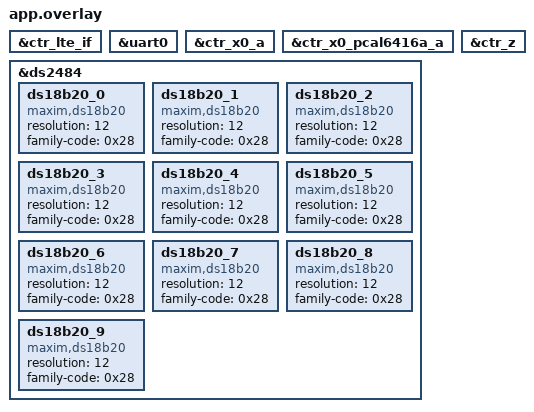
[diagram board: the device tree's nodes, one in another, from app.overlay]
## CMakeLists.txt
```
#
# Copyright (c) 2024 HARDWARIO a.s.
#
#  SPDX-License-Identifier: LicenseRef-HARDWARIO-5-Clause
#

cmake_minimum_required(VERSION 3.20.0)

set(ENV{FW_BUNDLE} "com.hardwario.chester.input")
set(ENV{FW_VERSION} "v1.0.0")
set(ENV{FW_NAME} "CHESTER Input")

find_package(Zephyr REQUIRED HINTS $ENV{ZEPHYR_BASE})

project(chester-input)

target_sources(app PRIVATE src/app_sensor.c)
target_sources(app PRIVATE src/main.c)
target_sources(app PRIVATE src/app_shell.c)
target_sources(app PRIVATE src/app_init.c)
target_sources(app PRIVATE src/app_data.c)
target_sources(app PRIVATE src/app_power.c)
target_sources(app PRIVATE src/app_send.c)
target_sources(app PRIVATE src/app_config.c)
target_sources(app PRIVATE src/app_work.c)
target_sources(app PRIVATE src/app_handler.c)
target_sources(app PRIVATE src/app_backup.c)
target_sources(app PRIVATE src/app_cbor.c)
```

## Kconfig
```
#
# Copyright (c) 2024 HARDWARIO a.s.
#
# SPDX-License-Identifier: LicenseRef-HARDWARIO-5-Clause
#

menu "Application"

# CHESTER INPUT Project | INPUT Variant 

# LTE 
config SHIELD_CTR_LTE
	bool "Enable SHIELD_CTR_LTE"
	default y 

config CTR_LTE
	default y
# X0_A 
config SHIELD_CTR_X0_A
	bool "Enable SHIELD_CTR_X0_A"
	default y 

config CTR_X0
	default y
# Z 
config SHIELD_CTR_Z
	bool "Enable SHIELD_CTR_Z"
	default y 

config CTR_Z
	default y

config I2C
	default y
# DS18B20 
config SHIELD_CTR_DS18B20
	bool "Enable SHIELD_CTR_DS18B20"
	default y 

config CTR_DS18B20
	default y

endmenu

menu "Zephyr Kernel"
source "Kconfig.zephyr"
endmenu
```

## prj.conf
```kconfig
#
# Copyright (c) 2024 HARDWARIO a.s.
#
#  SPDX-License-Identifier: LicenseRef-HARDWARIO-5-Clause
#

# Configurations
CONFIG_ADC_SHELL=y
CONFIG_CTR_ACCEL=y
CONFIG_CTR_ADC=y
CONFIG_CTR_BATT=y
CONFIG_CTR_BUTTON=y
CONFIG_CTR_BLE=y
CONFIG_CTR_BUF=y
CONFIG_CTR_DEFAULTS=y
CONFIG_CTR_EDGE=y
CONFIG_CTR_INFO=y
CONFIG_CTR_LED=y
CONFIG_CTR_LOG=y
CONFIG_CTR_LTE_CLKSYNC=y
CONFIG_CTR_RTC=y
CONFIG_CTR_THERM=y
CONFIG_CTR_WDOG=y
CONFIG_ENTROPY_GENERATOR=y
CONFIG_TINYCRYPT=y
CONFIG_TINYCRYPT_SHA256=y
CONFIG_ZCBOR=y
CONFIG_ZCBOR_STOP_ON_ERROR=y

# Extra configurations
CONFIG_ADC_TLA2021_INIT_PRIORITY=60
CONFIG_ADC_SHELL=n

# USER CODE BEGIN Config 
# USER CODE END Config
```

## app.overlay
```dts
/*
 * Copyright (c) 2024 HARDWARIO a.s.
 *
 * SPDX-License-Identifier: LicenseRef-HARDWARIO-5-Clause
 */

/* CHESTER INPUT Project | INPUT Variant */

/* LTE  */
&ctr_lte_if {
	status = "okay";
};

&uart0 {
	status = "okay";
};
/* X0_A  */
&ctr_x0_a {
	status = "okay";
};

&ctr_x0_pcal6416a_a {
	status = "okay";
};
/* Z  */
&ctr_z {
	status = "okay";
};
/* DS18B20  */
&ds2484 {
	ds18b20_0: ds18b20_0 {
		compatible = "maxim,ds18b20";
		resolution = <12>;
		family-code = <0x28>;
	};

	ds18b20_1: ds18b20_1 {
		compatible = "maxim,ds18b20";
		resolution = <12>;
		family-code = <0x28>;
	};

	ds18b20_2: ds18b20_2 {
		compatible = "maxim,ds18b20";
		resolution = <12>;
		family-code = <0x28>;
	};

	ds18b20_3: ds18b20_3 {
		compatible = "maxim,ds18b20";
		resolution = <12>;
		family-code = <0x28>;
	};

	ds18b20_4: ds18b20_4 {
		compatible = "maxim,ds18b20";
		resolution = <12>;
		family-code = <0x28>;
	};

	ds18b20_5: ds18b20_5 {
		compatible = "maxim,ds18b20";
		resolution = <12>;
		family-code = <0x28>;
	};

	ds18b20_6: ds18b20_6 {
		compatible = "maxim,ds18b20";
		resolution = <12>;
		family-code = <0x28>;
	};

	ds18b20_7: ds18b20_7 {
		compatible = "maxim,ds18b20";
		resolution = <12>;
		family-code = <0x28>;
	};

	ds18b20_8: ds18b20_8 {
		compatible = "maxim,ds18b20";
		resolution = <12>;
		family-code = <0x28>;
	};

	ds18b20_9: ds18b20_9 {
		compatible = "maxim,ds18b20";
		resolution = <12>;
		family-code = <0x28>;
	};
};
```

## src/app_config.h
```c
/*
 * Copyright (c) 2024 HARDWARIO a.s.
 *
 * SPDX-License-Identifier: LicenseRef-HARDWARIO-5-Clause
 */

#ifndef APP_CONFIG_H_
#define APP_CONFIG_H_

/* Zephyr includes */
#include <zephyr/shell/shell.h>

/* Standard includes */
#include <stdbool.h>
#include <stddef.h>

/* USER CODE BEGIN Includes */
/* USER CODE END Includes */

#ifdef __cplusplus
extern "C" {
#endif

enum app_config_input_type {
	APP_CONFIG_INPUT_TYPE_NPN = 0,
	APP_CONFIG_INPUT_TYPE_PNP = 1,
};

struct app_config {
	enum app_config_input_type trigger_input_type;
	enum app_config_input_type counter_input_type;
	int interval_report;
	int event_report_delay;
	int event_report_rate;
	bool backup_report_connected;
	bool backup_report_disconnected;
	int trigger_duration_active;
	int trigger_duration_inactive;
	int trigger_cooldown_time;
	bool trigger_report_active;
	bool trigger_report_inactive;
	int counter_interval_aggreg;
	int counter_duration_active;
	int counter_duration_inactive;
	int counter_cooldown_time;
	int analog_interval_sample;
	int analog_interval_aggreg;
	int hygro_interval_sample;
	int hygro_interval_aggreg;
	int w1_therm_interval_sample;
	int w1_therm_interval_aggreg;

	/* USER CODE BEGIN Struct Variables */
	/* USER CODE END Struct Variables */
};

extern struct app_config g_app_config;

/* USER CODE BEGIN Variables */
/* USER CODE END Variables */

int app_config_cmd_config_show(const struct shell *shell, size_t argc, char **argv);
int app_config_cmd_config_interval_report(const struct shell *shell, size_t argc, char **argv);
int app_config_cmd_config_event_report_delay(const struct shell *shell, size_t argc, char **argv);
int app_config_cmd_config_event_report_rate(const struct shell *shell, size_t argc, char **argv);
int app_config_cmd_config_backup_report_connected(const struct shell *shell, size_t argc, char **argv);
int app_config_cmd_config_backup_report_disconnected(const struct shell *shell, size_t argc, char **argv);
int app_config_cmd_config_trigger_duration_active(const struct shell *shell, size_t argc, char **argv);
int app_config_cmd_config_trigger_duration_inactive(const struct shell *shell, size_t argc, char **argv);
int app_config_cmd_config_trigger_cooldown_time(const struct shell *shell, size_t argc, char **argv);
int app_config_cmd_config_trigger_report_active(const struct shell *shell, size_t argc, char **argv);
int app_config_cmd_config_trigger_report_inactive(const struct shell *shell, size_t argc, char **argv);
int app_config_cmd_config_counter_interval_aggreg(const struct shell *shell, size_t argc, char **argv);
int app_config_cmd_config_counter_duration_active(const struct shell *shell, size_t argc, char **argv);
int app_config_cmd_config_counter_duration_inactive(const struct shell *shell, size_t argc, char **argv);
int app_config_cmd_config_counter_cooldown_time(const struct shell *shell, size_t argc, char **argv);
int app_config_cmd_config_analog_interval_sample(const struct shell *shell, size_t argc, char **argv);
int app_config_cmd_config_analog_interval_aggreg(const struct shell *shell, size_t argc, char **argv);
int app_config_cmd_config_hygro_interval_sample(const struct shell *shell, size_t argc, char **argv);
int app_config_cmd_config_hygro_interval_aggreg(const struct shell *shell, size_t argc, char **argv);
int app_config_cmd_config_w1_therm_interval_sample(const struct shell *shell, size_t argc, char **argv);
int app_config_cmd_config_w1_therm_interval_aggreg(const struct shell *shell, size_t argc, char **argv);
int app_config_cmd_config_trigger_input_type(const struct shell *shell, size_t argc, char **argv);
int app_config_cmd_config_counter_input_type(const struct shell *shell, size_t argc, char **argv);

/* USER CODE BEGIN Functions 1 */
/* USER CODE END Functions 1 */

#ifdef __cplusplus
}
#endif

#endif /* APP_CONFIG_H_ */
```

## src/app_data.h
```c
/*
 * Copyright (c) 2023 HARDWARIO a.s.
 *
 * SPDX-License-Identifier: LicenseRef-HARDWARIO-5-Clause
 */

#ifndef APP_DATA_H_
#define APP_DATA_H_

/* CHESTER includes */
#include <chester/ctr_edge.h>
#include <chester/ctr_lte.h>

/* Standard includes */
#include <stdbool.h>
#include <stdint.h>

/* TODO Delete */
#include <zephyr/kernel.h>

#define APP_DATA_ANALOG_MAX_SAMPLES      32
#define APP_DATA_ANALOG_MAX_MEASUREMENTS 32

#define APP_DATA_COUNTER_MAX_MEASUREMENTS 32

#define APP_DATA_MAX_TRIGGER_EVENTS 32
#define APP_DATA_MAX_BACKUP_EVENTS  32

#define APP_DATA_HYGRO_MAX_SAMPLES      32
#define APP_DATA_HYGRO_MAX_MEASUREMENTS 32

#if defined(CONFIG_SHIELD_CTR_DS18B20)
#define APP_DATA_W1_THERM_COUNT            10
#define APP_DATA_W1_THERM_MAX_SAMPLES      128
#define APP_DATA_W1_THERM_MAX_MEASUREMENTS 32
#endif /* defined(CONFIG_SHIELD_CTR_DS18B20) */

#ifdef __cplusplus
extern "C" {
#endif

struct app_data_aggreg {
	float min;
	float max;
	float avg;
	float mdn;
};

#if defined(CONFIG_SHIELD_CTR_Z)

struct app_data_backup_event {
	int64_t timestamp;
	bool connected;
};

struct app_data_backup {
	float line_voltage;
	float battery_voltage;
	bool line_present;
	int event_count;
	struct app_data_backup_event events[APP_DATA_MAX_BACKUP_EVENTS];
};

#endif /* defined(CONFIG_SHIELD_CTR_Z) */

#if defined(CONFIG_SHIELD_CTR_X0_A)

struct app_data_trigger_event {
	int64_t timestamp;
	bool is_active;
};

struct app_data_trigger {
	bool trigger_active;
	int event_count;
	struct app_data_trigger_event events[APP_DATA_MAX_TRIGGER_EVENTS];
};

struct app_data_counter_measurement {
	uint64_t value;
};

struct app_data_counter {
	int64_t timestamp;
	uint64_t value;
	uint64_t delta;
	int measurement_count;
	struct app_data_counter_measurement measurements[APP_DATA_COUNTER_MAX_MEASUREMENTS];
};

struct app_data_analog {
	int64_t timestamp;
	int sample_count;
	float samples[APP_DATA_ANALOG_MAX_SAMPLES];
	int measurement_count;
	struct app_data_aggreg measurements[APP_DATA_ANALOG_MAX_MEASUREMENTS];
};

#endif /* defined(CONFIG_SHIELD_CTR_X0_A) */

#if defined(CONFIG_SHIELD_CTR_S2)

struct app_data_hygro_measurement {
	struct app_data_aggreg temperature;
	struct app_data_aggreg humidity;
};

struct app_data_hygro {
	int64_t timestamp;
	int sample_count;
	float samples_temperature[APP_DATA_HYGRO_MAX_SAMPLES];
	float samples_humidity[APP_DATA_HYGRO_MAX_SAMPLES];
	int measurement_count;
	struct app_data_hygro_measurement measurements[APP_DATA_HYGRO_MAX_MEASUREMENTS];
};

#endif /* defined(CONFIG_SHIELD_CTR_S2) */

#if defined(CONFIG_SHIELD_CTR_DS18B20)
struct app_data_w1_therm_measurement {
	struct app_data_aggreg temperature;
};

struct app_data_w1_therm_sensor {
	uint64_t serial_number;

	float last_sample_temperature;

	int sample_count;
	float samples_temperature[APP_DATA_W1_THERM_MAX_SAMPLES];

	int measurement_count;
	struct app_data_w1_therm_measurement measurements[APP_DATA_W1_THERM_MAX_MEASUREMENTS];
};

struct app_data_w1_therm {
	struct app_data_w1_therm_sensor sensor[APP_DATA_W1_THERM_COUNT];

	int64_t timestamp;
	atomic_t sample;
	atomic_t aggreg;
};
#endif /* defined(CONFIG_SHIELD_CTR_DS18B20) */

struct app_data {
	float system_voltage_rest;
	float system_voltage_load;
	float system_current_load;
	float therm_temperature;
	float accel_acceleration_x;
	float accel_acceleration_y;
	float accel_acceleration_z;
	int accel_orientation;

#if defined(CONFIG_SHIELD_CTR_Z)
	struct app_data_backup backup;
#endif /* defined(CONFIG_SHIELD_CTR_Z) */

#if defined(CONFIG_SHIELD_CTR_X0_A)
	struct app_data_counter counter;
	struct app_data_trigger trigger;
	struct app_data_analog voltage;
	struct app_data_analog current;
#endif /* defined(CONFIG_SHIELD_CTR_X0_A) */

#if defined(CONFIG_SHIELD_CTR_S2)
	struct app_data_hygro hygro;
#endif /* defined(CONFIG_SHIELD_CTR_S2) */

#if defined(CONFIG_SHIELD_CTR_DS18B20)
	struct app_data_w1_therm w1_therm;
#endif /* defined(CONFIG_SHIELD_CTR_DS18B20) */
};

extern struct app_data g_app_data;

/* TODO Delete */
extern struct k_mutex g_app_data_lte_eval_mut;
extern bool g_app_data_lte_eval_valid;
extern struct ctr_lte_eval g_app_data_lte_eval;

void app_data_lock(void);
void app_data_unlock(void);

#ifdef __cplusplus
}
#endif

#endif /* APP_DATA_H_ */
```

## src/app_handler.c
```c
/*
 * Copyright (c) 2023 HARDWARIO a.s.
 *
 * SPDX-License-Identifier: LicenseRef-HARDWARIO-5-Clause
 */

#include "app_config.h"
#include "app_data.h"
#include "app_handler.h"
#include "app_init.h"
#include "app_work.h"

/* CHESTER includes */
#include <chester/ctr_led.h>
#include <chester/ctr_lte.h>
#include <chester/ctr_rtc.h>
#include <chester/drivers/ctr_z.h>

/* Zephyr includes */
#include <zephyr/kernel.h>
#include <zephyr/logging/log.h>
#include <zephyr/sys/reboot.h>

/* Standard includes */
#include <inttypes.h>
#include <math.h>
#include <stdbool.h>
#include <stddef.h>

LOG_MODULE_REGISTER(app_handler, LOG_LEVEL_DBG);

static atomic_t m_report_rate_hourly_counter = 0;
static atomic_t m_report_rate_timer_is_active = false;
static atomic_t m_report_delay_timer_is_active = false;

#if defined(CONFIG_SHIELD_CTR_LTE)

static void start(void)
{
	int ret;

	ret = ctr_lte_start(NULL);
	if (ret) {
		LOG_ERR("Call `ctr_lte_start` failed: %d", ret);
		k_oops();
	}
}

static void attach(void)
{
	int ret;

	ret = ctr_lte_attach(NULL);
	if (ret) {
		LOG_ERR("Call `ctr_lte_attach` failed: %d", ret);
		k_oops();
	}
}

void app_handler_lte(enum ctr_lte_event event, union ctr_lte_event_data *data, void *param)
{
	switch (event) {
	case CTR_LTE_EVENT_FAILURE:
		LOG_ERR("Event `CTR_LTE_EVENT_FAILURE`");
		start();
		break;

	case CTR_LTE_EVENT_START_OK:
		LOG_INF("Event `CTR_LTE_EVENT_START_OK`");
		attach();
		break;

	case CTR_LTE_EVENT_START_ERR:
		LOG_ERR("Event `CTR_LTE_EVENT_START_ERR`");
		start();
		break;

	case CTR_LTE_EVENT_ATTACH_OK:
		LOG_INF("Event `CTR_LTE_EVENT_ATTACH_OK`");
		k_sem_give(&g_app_init_sem);
		break;

	case CTR_LTE_EVENT_ATTACH_ERR:
		LOG_ERR("Event `CTR_LTE_EVENT_ATTACH_ERR`");
		start();
		break;

	case CTR_LTE_EVENT_DETACH_OK:
		LOG_INF("Event `CTR_LTE_EVENT_DETACH_OK`");
		break;

	case CTR_LTE_EVENT_DETACH_ERR:
		LOG_ERR("Event `CTR_LTE_EVENT_DETACH_ERR`");
		start();
		break;

	case CTR_LTE_EVENT_EVAL_OK:
		LOG_INF("Event `CTR_LTE_EVENT_EVAL_OK`");

		struct ctr_lte_eval *eval = &data->eval_ok.eval;

		LOG_DBG("EEST: %d", eval->eest);
		LOG_DBG("ECL: %d", eval->ecl);
		LOG_DBG("RSRP: %d", eval->rsrp);
		LOG_DBG("RSRQ: %d", eval->rsrq);
		LOG_DBG("SNR: %d", eval->snr);
		LOG_DBG("PLMN: %d", eval->plmn);
		LOG_DBG("CID: %d", eval->cid);
		LOG_DBG("BAND: %d", eval->band);
		LOG_DBG("EARFCN: %d", eval->earfcn);

		k_mutex_lock(&g_app_data_lte_eval_mut, K_FOREVER);
		memcpy(&g_app_data_lte_eval, &data->eval_ok.eval, sizeof(g_app_data_lte_eval));
		g_app_data_lte_eval_valid = true;
		k_mutex_unlock(&g_app_data_lte_eval_mut);

		break;

	case CTR_LTE_EVENT_EVAL_ERR:
		LOG_ERR("Event `CTR_LTE_EVENT_EVAL_ERR`");

		k_mutex_lock(&g_app_data_lte_eval_mut, K_FOREVER);
		g_app_data_lte_eval_valid = false;
		k_mutex_unlock(&g_app_data_lte_eval_mut);

		break;

	case CTR_LTE_EVENT_SEND_OK:
		LOG_INF("Event `CTR_LTE_EVENT_SEND_OK`");
		break;

	case CTR_LTE_EVENT_SEND_ERR:
		LOG_ERR("Event `CTR_LTE_EVENT_SEND_ERR`");
		start();
		break;

	default:
		LOG_WRN("Unknown event: %d", event);
		return;
	}
}

#endif /* defined(CONFIG_SHIELD_CTR_LTE) */

static void report_delay_timer_handler(struct k_timer *timer)
{
	app_work_send();
	atomic_inc(&m_report_rate_hourly_counter);
	atomic_set(&m_report_delay_timer_is_active, false);
}

static K_TIMER_DEFINE(m_report_delay_timer, report_delay_timer_handler, NULL);

static void report_rate_timer_handler(struct k_timer *timer)
{
	atomic_set(&m_report_rate_hourly_counter, 0);
	atomic_set(&m_report_rate_timer_is_active, false);
}

static K_TIMER_DEFINE(m_report_rate_timer, report_rate_timer_handler, NULL);

#if defined(CONFIG_SHIELD_CTR_X0_A) || defined(CONFIG_SHIELD_CTR_Z)

static void send_with_rate_limit(void)
{
	if (!atomic_get(&m_report_rate_timer_is_active)) {
		k_timer_start(&m_report_rate_timer, K_HOURS(1), K_NO_WAIT);
		atomic_set(&m_report_rate_timer_is_active, true);
	}

	LOG_INF("Hourly counter state: %d/%d", (int)atomic_get(&m_report_rate_hourly_counter),
		g_app_config.event_report_rate);

	if (atomic_get(&m_report_rate_hourly_counter) <= g_app_config.event_report_rate) {
		if (!atomic_get(&m_report_delay_timer_is_active)) {
			LOG_INF("Starting delay timer");
			k_timer_start(&m_report_delay_timer,
				      K_SECONDS(g_app_config.event_report_delay), K_NO_WAIT);
			atomic_set(&m_report_delay_timer_is_active, true);
		} else {
			LOG_INF("Delay timer already running");
		}
	} else {
		LOG_WRN("Hourly counter exceeded");
	}
}

#endif

#if defined(CONFIG_SHIELD_CTR_X0_A)

void app_handler_edge_trigger_callback(struct ctr_edge *edge, enum ctr_edge_event edge_event,
				       void *user_data)
{
	int ret;

	struct app_data_trigger *trigger = &g_app_data.trigger;

	app_data_lock();

	if (trigger->event_count < APP_DATA_MAX_TRIGGER_EVENTS) {
		struct app_data_trigger_event *event = &trigger->events[trigger->event_count];

		ret = ctr_rtc_get_ts(&event->timestamp);
		if (ret) {
			LOG_ERR("Call `ctr_rtc_get_ts` failed: %d", ret);
			app_data_unlock();
			return;
		}

		event->is_active = edge_event == CTR_EDGE_EVENT_ACTIVE;
		trigger->event_count++;

		LOG_INF("Event count: %d", trigger->event_count);
	} else {
		LOG_WRN("Measurement full");
		app_data_unlock();
		return;
	}

	trigger->trigger_active = edge_event == CTR_EDGE_EVENT_ACTIVE;

	LOG_INF("Input: %d", (int)trigger->trigger_active);

	if (g_app_config.trigger_report_active && edge_event == CTR_EDGE_EVENT_ACTIVE) {
		send_with_rate_limit();
	}

	if (g_app_config.trigger_report_inactive && edge_event == CTR_EDGE_EVENT_INACTIVE) {
		send_with_rate_limit();
	}

	app_data_unlock();
}

void app_handler_edge_counter_callback(struct ctr_edge *edge, enum ctr_edge_event edge_event,
				       void *user_data)
{
	if (edge_event == CTR_EDGE_EVENT_ACTIVE) {
		app_data_lock();

		g_app_data.counter.value++;
		g_app_data.counter.delta++;
		LOG_INF("Counter: %llu", g_app_data.counter.value);

		app_data_unlock();
	}
}

#endif /* defined(CONFIG_SHIELD_CTR_X0_A) */

#if defined(CONFIG_SHIELD_CTR_Z)

void app_handler_ctr_z(const struct device *dev, enum ctr_z_event backup_event, void *param)
{
	int ret;

	if (backup_event != CTR_Z_EVENT_DC_CONNECTED &&
	    backup_event != CTR_Z_EVENT_DC_DISCONNECTED) {
		return;
	}

	struct app_data_backup *backup = &g_app_data.backup;

	app_work_backup_update();

	app_data_lock();

	backup->line_present = backup_event == CTR_Z_EVENT_DC_CONNECTED;

	if (backup->event_count < APP_DATA_MAX_BACKUP_EVENTS) {
		struct app_data_backup_event *event = &backup->events[backup->event_count];

		ret = ctr_rtc_get_ts(&event->timestamp);
		if (ret) {
			LOG_ERR("Call `ctr_rtc_get_ts` failed: %d", ret);
			app_data_unlock();
			return;
		}

		event->connected = backup->line_present;
		backup->event_count++;

		LOG_INF("Event count: %d", backup->event_count);
	} else {
		LOG_WRN("Measurement full");
		app_data_unlock();
		return;
	}

	LOG_INF("Backup: %d", (int)backup->line_present);

	if (g_app_config.backup_report_connected && backup_event == CTR_Z_EVENT_DC_CONNECTED) {
		send_with_rate_limit();
	}

	if (g_app_config.backup_report_disconnected &&
	    backup_event == CTR_Z_EVENT_DC_DISCONNECTED) {
		send_with_rate_limit();
	}

	app_data_unlock();
}

#endif /* defined(CONFIG_SHIELD_CTR_Z) */

#if defined(CONFIG_CTR_BUTTON)

static void app_load_timer_handler(struct k_timer *timer)
{
	ctr_led_set(CTR_LED_CHANNEL_LOAD, 0);
}

K_TIMER_DEFINE(app_load_timer, app_load_timer_handler, NULL);

void app_handler_ctr_button(enum ctr_button_channel chan, enum ctr_button_event ev, int val,
			    void *user_data)
{
	int ret;

	if (chan != CTR_BUTTON_CHANNEL_INT) {
		return;
	}

	if (ev == CTR_BUTTON_EVENT_CLICK) {
		for (int i = 0; i < val; i++) {
			ret = ctr_led_set(CTR_LED_CHANNEL_Y, true);
			if (ret) {
				LOG_ERR("Call `ctr_led_set` failed: %d", ret);
				return;
			}

			k_sleep(K_MSEC(50));
			ret = ctr_led_set(CTR_LED_CHANNEL_Y, false);
			if (ret) {
				LOG_ERR("Call `ctr_led_set` failed: %d", ret);
				return;
			}

			k_sleep(K_MSEC(200));
		}

		switch (val) {
		case 1:
			app_work_send();
			break;
		case 2:
			app_work_sample();
			break;
		case 3:
			app_work_sample();
			app_work_aggreg();
			app_work_send();
			break;
		case 4:
			sys_reboot(SYS_REBOOT_COLD);
			break;
		case 5:
			ret = ctr_led_set(CTR_LED_CHANNEL_LOAD, 1);
			if (ret) {
				LOG_ERR("Call `ctr_led_set` failed: %d", ret);
				return;
			}
			k_timer_start(&app_load_timer, K_MINUTES(2), K_FOREVER);
			break;
		}
	}
}

#endif /* defined(CONFIG_CTR_BUTTON) */
```

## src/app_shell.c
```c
/*
 * Copyright (c) 2024 HARDWARIO a.s.
 *
 * SPDX-License-Identifier: LicenseRef-HARDWARIO-5-Clause
 */

#include "app_config.h"
#include "app_work.h"

/* Zephyr includes */
#include <zephyr/kernel.h>
#include <zephyr/logging/log.h>
#include <zephyr/shell/shell.h>

/* Standard includes */
#include <errno.h>
#include <stdlib.h>

/* USER CODE BEGIN Includes */
/* USER CODE END Includes */

LOG_MODULE_REGISTER(app_shell, LOG_LEVEL_INF);

static int cmd_sample(const struct shell *shell, size_t argc, char **argv)
{
	if (argc > 1) {
		shell_error(shell, "unknown parameter: %s", argv[1]);
		shell_help(shell);
		return -EINVAL;
	}

	app_work_sample();

	return 0;
}

static int cmd_send(const struct shell *shell, size_t argc, char **argv)
{
	if (argc > 1) {
		shell_error(shell, "unknown parameter: %s", argv[1]);
		shell_help(shell);
		return -EINVAL;
	}

	app_work_send();

	return 0;
}

static int cmd_aggreg(const struct shell *shell, size_t argc, char **argv)
{
	if (argc > 1) {
		shell_error(shell, "unknown parameter: %s", argv[1]);
		shell_help(shell);
		return -EINVAL;
	}

	app_work_aggreg();

	return 0;
}

static int print_help(const struct shell *shell, size_t argc, char **argv)
{
	if (argc > 1) {
		shell_error(shell, "command not found: %s", argv[1]);
		shell_help(shell);
		return -EINVAL;
	}

	shell_help(shell);
	return 0;
}

/* clang-format off */

SHELL_STATIC_SUBCMD_SET_CREATE(
	sub_app_config,
   
	SHELL_CMD_ARG(show, NULL,
				  "List current configuration.",
				  app_config_cmd_config_show, 1, 0),
	
	SHELL_CMD_ARG(interval-report, NULL,
				  "Get/Set report interval in seconds (format: <30-86400>).",
				  app_config_cmd_config_interval_report, 1, 1),
	
	SHELL_CMD_ARG(event-report-delay, NULL,
				  "Get/Set event report delay in seconds (format: <1-86400>).",
				  app_config_cmd_config_event_report_delay, 1, 1),
	
	SHELL_CMD_ARG(event-report-rate, NULL,
				  "Get/Set event report rate in reports per hour (format: <1-3600>).",
				  app_config_cmd_config_event_report_rate, 1, 1),
	
	SHELL_CMD_ARG(backup-report-connected, NULL,
				  "Get/Set report when backup is active (format: true, false).",
				  app_config_cmd_config_backup_report_connected, 1, 1),
	
	SHELL_CMD_ARG(backup-report-disconnected, NULL,
				  "Get/Set report when backup is inactive (format: true, false).",
				  app_config_cmd_config_backup_report_disconnected, 1, 1),
	
	SHELL_CMD_ARG(trigger-active-duration, NULL,
				  "Get/Set event active duration in milliseconds (format: <0-60000>).",
				  app_config_cmd_config_trigger_duration_active, 1, 1),
	
	SHELL_CMD_ARG(trigger-inactive-duration, NULL,
				  "Get/Set event inactive duration in milliseconds (format: <0-60000>).",
				  app_config_cmd_config_trigger_duration_inactive, 1, 1),
	
	SHELL_CMD_ARG(trigger-cooldown-time, NULL,
				  "Get/Set trigger cooldown time in milliseconds (format: <0-60000>).",
				  app_config_cmd_config_trigger_cooldown_time, 1, 1),
	
	SHELL_CMD_ARG(trigger-report-active, NULL,
				  "Get/Set report when trigger is active (format: true, false).",
				  app_config_cmd_config_trigger_report_active, 1, 1),
	
	SHELL_CMD_ARG(trigger-report-inactive, NULL,
				  "Get/Set report when trigger is inactive (format: true, false).",
				  app_config_cmd_config_trigger_report_inactive, 1, 1),
	
	SHELL_CMD_ARG(counter-interval-aggreg, NULL,
				  "Get/Set counter aggregation interval in seconds (format: <1-86400>).",
				  app_config_cmd_config_counter_interval_aggreg, 1, 1),
	
	SHELL_CMD_ARG(counter-duration-active, NULL,
				  "Get/Set event active duration in milliseconds (format: <0-60000>).",
				  app_config_cmd_config_counter_duration_active, 1, 1),
	
	SHELL_CMD_ARG(counter-duration-inactive, NULL,
				  "Get/Set event inactive duration in milliseconds (format: <0-60000>).",
				  app_config_cmd_config_counter_duration_inactive, 1, 1),
	
	SHELL_CMD_ARG(counter-cooldown-time, NULL,
				  "Get/Set counter cooldown time in milliseconds (format: <0-60000>).",
				  app_config_cmd_config_counter_cooldown_time, 1, 1),
	
	SHELL_CMD_ARG(analog-interval-sample, NULL,
				  "Get/Set analog sample interval in seconds (format: <1-86400>).",
				  app_config_cmd_config_analog_interval_sample, 1, 1),
	
	SHELL_CMD_ARG(analog-interval-aggreg, NULL,
				  "Get/Set analog aggregation interval in seconds (format: <1-86400>).",
				  app_config_cmd_config_analog_interval_aggreg, 1, 1),
	
	SHELL_CMD_ARG(hygro-interval-sample, NULL,
				  "Get/Set hygro sample interval in seconds (format: <1-86400>).",
				  app_config_cmd_config_hygro_interval_sample, 1, 1),
	
	SHELL_CMD_ARG(hygro-interval-aggreg, NULL,
				  "Get/Set hygro aggreg interval in seconds (format: <1-86400>).",
				  app_config_cmd_config_hygro_interval_aggreg, 1, 1),
	
	SHELL_CMD_ARG(w1-therm-interval-sample, NULL,
				  "Get/Set ds18b20 sample interval in seconds (format: <1-86400>).",
				  app_config_cmd_config_w1_therm_interval_sample, 1, 1),
	
	SHELL_CMD_ARG(w1-therm-interval-aggreg, NULL,
				  "Get/Set ds18b20 aggregation interval in seconds (format: <1-86400>).",
				  app_config_cmd_config_w1_therm_interval_aggreg, 1, 1),
	
	/* USER CODE BEGIN Functions 1 */
	/* USER CODE END Functions 1 */

	SHELL_SUBCMD_SET_END
);

SHELL_STATIC_SUBCMD_SET_CREATE(
	sub_app,

	SHELL_CMD_ARG(config, &sub_app_config, "Configuration commands.",
				  print_help, 1, 0),
		
	SHELL_SUBCMD_SET_END

	/* USER CODE BEGIN Functions 2 */
	/* USER CODE END Functions 2 */
);

SHELL_CMD_REGISTER(app, &sub_app, "Application commands.", print_help);

SHELL_CMD_REGISTER(sample, NULL,"Sample immediately.", cmd_sample);
SHELL_CMD_REGISTER(send, NULL,"Send data immediately.", cmd_send);
SHELL_CMD_REGISTER(aggreg, NULL,"Aggregate data immediately", cmd_aggreg);

/* USER CODE BEGIN Functions 3 */
/* USER CODE END Functions 3 */

/* clang-format on */
```

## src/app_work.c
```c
/*
 * Copyright (c) 2023 HARDWARIO a.s.
 *
 * SPDX-License-Identifier: LicenseRef-HARDWARIO-5-Clause
 */

#include "app_backup.h"
#include "app_config.h"
#include "app_data.h"
#include "app_init.h"
#include "app_power.h"
#include "app_send.h"
#include "app_sensor.h"
#include "app_work.h"

/* Zephyr includes */
#include <zephyr/device.h>
#include <zephyr/kernel.h>
#include <zephyr/logging/log.h>
#include <zephyr/random/rand32.h>

/* Standard includes */
#include <math.h>
#include <stddef.h>
#include <stdint.h>

LOG_MODULE_REGISTER(app_work, LOG_LEVEL_DBG);

#define WORK_Q_STACK_SIZE 4096
#define WORK_Q_PRIORITY   K_LOWEST_APPLICATION_THREAD_PRIO

static struct k_work_q m_work_q;
static K_THREAD_STACK_DEFINE(m_work_q_stack, WORK_Q_STACK_SIZE);

static struct k_timer m_send_timer;

static void send_work_handler(struct k_work *work)
{
	int ret;

	int64_t jitter = (int32_t)sys_rand32_get() % (g_app_config.interval_report * 1000 / 5);
	int64_t duration = g_app_config.interval_report * 1000 + jitter;

	LOG_INF("Scheduling next timeout in %lld second(s)", duration / 1000);

	k_timer_start(&m_send_timer, K_MSEC(duration), K_FOREVER);

	ret = app_send();
	if (ret) {
		LOG_ERR("Call `app_send` failed: %d", ret);
	}

#if defined(CONFIG_SHIELD_CTR_Z)
	app_backup_clear();
#endif /* defined(CONFIG_SHIELD_CTR_Z) */

#if defined(CONFIG_SHIELD_CTR_X0_A)
	app_sensor_trigger_clear();
	app_sensor_counter_clear();
	app_sensor_voltage_clear();
	app_sensor_current_clear();
#endif /* defined(CONFIG_SHIELD_CTR_X0_A) */

#if defined(CONFIG_SHIELD_CTR_S2)
	app_sensor_hygro_clear();
#endif /* defined(CONFIG_SHIELD_CTR_S2) */

#if defined(CONFIG_SHIELD_CTR_DS18B20)
	app_sensor_w1_therm_clear();
#endif /* defined(CONFIG_SHIELD_CTR_DS18B20) */
}

static K_WORK_DEFINE(m_send_work, send_work_handler);

static void send_timer_handler(struct k_timer *timer)
{
	int ret;

	ret = k_work_submit_to_queue(&m_work_q, &m_send_work);
	if (ret < 0) {
		LOG_ERR("Call `k_work_submit_to_queue` failed: %d", ret);
	}
}

static K_TIMER_DEFINE(m_send_timer, send_timer_handler, NULL);

static void sample_work_handler(struct k_work *work)
{
	int ret;

#if defined(CONFIG_SHIELD_CTR_Z)
	ret = app_backup_sample();
	if (ret) {
		LOG_ERR("Call `app_backup_sample` failed: %d", ret);
	}
#endif /* defined(CONFIG_SHIELD_CTR_Z) */

	ret = app_sensor_sample();
	if (ret < 0) {
		LOG_ERR("Call `app_sensor_sample` failed: %d", ret);
	}
}

static K_WORK_DEFINE(m_sample_work, sample_work_handler);

static void sample_timer_handler(struct k_timer *timer)
{
	int ret;

	ret = k_work_submit_to_queue(&m_work_q, &m_sample_work);
	if (ret < 0) {
		LOG_ERR("Call `k_work_submit_to_queue` failed: %d", ret);
	}
}

static K_TIMER_DEFINE(m_sample_timer, sample_timer_handler, NULL);

static void power_work_handler(struct k_work *work)
{
	int ret;

	ret = app_power_sample();
	if (ret < 0) {
		LOG_ERR("Call `app_power_sample` failed: %d", ret);
	}
}

static K_WORK_DEFINE(m_power_work, power_work_handler);

static void power_timer_handler(struct k_timer *timer)
{
	int ret;

	ret = k_work_submit_to_queue(&m_work_q, &m_power_work);
	if (ret < 0) {
		LOG_ERR("Call `k_work_submit_to_queue` failed: %d", ret);
	}
}

static K_TIMER_DEFINE(m_power_timer, power_timer_handler, NULL);

#if defined(CONFIG_SHIELD_CTR_X0_A)

static void counter_aggreg_work_handler(struct k_work *work)
{
	int ret;

	ret = app_sensor_counter_aggreg();
	if (ret < 0) {
		LOG_ERR("Call `app_sensor_counter_aggreg` failed: %d", ret);
	}
}

static K_WORK_DEFINE(m_counter_aggreg_work, counter_aggreg_work_handler);

static void counter_aggreg_timer_handler(struct k_timer *timer)
{
	int ret;

	ret = k_work_submit_to_queue(&m_work_q, &m_counter_aggreg_work);
	if (ret < 0) {
		LOG_ERR("Call `k_work_submit_to_queue` failed: %d", ret);
	}
}

static K_TIMER_DEFINE(m_counter_aggreg_timer, counter_aggreg_timer_handler, NULL);

static void analog_sample_work_handler(struct k_work *work)
{
	int ret;

	ret = app_sensor_voltage_sample();
	if (ret < 0) {
		LOG_ERR("Call `app_sensor_voltage_sample` failed: %d", ret);
	}

	ret = app_sensor_current_sample();
	if (ret < 0) {
		LOG_ERR("Call `app_sensor_current_sample` failed: %d", ret);
	}
}

static K_WORK_DEFINE(m_analog_sample_work, analog_sample_work_handler);

static void analog_sample_timer_handler(struct k_timer *timer)
{
	int ret;

	ret = k_work_submit_to_queue(&m_work_q, &m_analog_sample_work);
	if (ret < 0) {
		LOG_ERR("Call `k_work_submit_to_queue` failed: %d", ret);
	}
}

static K_TIMER_DEFINE(m_analog_sample_timer, analog_sample_timer_handler, NULL);

static void analog_aggreg_work_handler(struct k_work *work)
{
	int ret;

	ret = app_sensor_voltage_aggreg();
	if (ret < 0) {
		LOG_ERR("Call `app_sensor_voltage_aggreg` failed: %d", ret);
	}

	ret = app_sensor_current_aggreg();
	if (ret < 0) {
		LOG_ERR("Call `app_sensor_current_aggreg` failed: %d", ret);
	}
}

static K_WORK_DEFINE(m_analog_aggreg_work, analog_aggreg_work_handler);

static void analog_aggreg_timer_handler(struct k_timer *timer)
{
	int ret;

	ret = k_work_submit_to_queue(&m_work_q, &m_analog_aggreg_work);
	if (ret < 0) {
		LOG_ERR("Call `k_work_submit_to_queue` failed: %d", ret);
	}
}

static K_TIMER_DEFINE(m_analog_aggreg_timer, analog_aggreg_timer_handler, NULL);

#endif /* defined(CONFIG_SHIELD_CTR_X0_A) */

#if defined(CONFIG_SHIELD_CTR_S2)

static void hygro_sample_work_handler(struct k_work *work)
{
	int ret;

	ret = app_sensor_hygro_sample();
	if (ret < 0) {
		LOG_ERR("Call `app_sensor_hygro_sample` failed: %d", ret);
	}
}

static K_WORK_DEFINE(m_hygro_sample_work, hygro_sample_work_handler);

static void hygro_sample_timer_handler(struct k_timer *timer)
{
	int ret;

	ret = k_work_submit_to_queue(&m_work_q, &m_hygro_sample_work);
	if (ret < 0) {
		LOG_ERR("Call `k_work_submit_to_queue` failed: %d", ret);
	}
}

static K_TIMER_DEFINE(m_hygro_sample_timer, hygro_sample_timer_handler, NULL);

static void hygro_aggreg_work_handler(struct k_work *work)
{
	int ret;

	ret = app_sensor_hygro_aggreg();
	if (ret < 0) {
		LOG_ERR("Call `app_sensor_hygro_aggreg` failed: %d", ret);
	}
}

static K_WORK_DEFINE(m_hygro_aggreg_work, hygro_aggreg_work_handler);

static void hygro_aggreg_timer_handler(struct k_timer *timer)
{
	int ret;

	ret = k_work_submit_to_queue(&m_work_q, &m_hygro_aggreg_work);
	if (ret < 0) {
		LOG_ERR("Call `k_work_submit_to_queue` failed: %d", ret);
	}
}

static K_TIMER_DEFINE(m_hygro_aggreg_timer, hygro_aggreg_timer_handler, NULL);

#endif /* defined(CONFIG_SHIELD_CTR_S2) */

#if defined(CONFIG_SHIELD_CTR_DS18B20)

static void w1_therm_sample_work_handler(struct k_work *work)
{
	int ret;

	ret = app_sensor_w1_therm_sample();
	if (ret) {
		LOG_ERR("Call `app_sensor_w1_therm_sample` failed: %d", ret);
	}
}

static K_WORK_DEFINE(m_w1_therm_sample_work, w1_therm_sample_work_handler);

static void w1_therm_sample_timer_handler(struct k_timer *timer)
{
	int ret;

	ret = k_work_submit_to_queue(&m_work_q, &m_w1_therm_sample_work);
	if (ret < 0) {
		LOG_ERR("Call `k_work_submit_to_queue` failed: %d", ret);
	}
}

static K_TIMER_DEFINE(m_w1_therm_sample_timer, w1_therm_sample_timer_handler, NULL);

static void w1_therm_aggreg_work_handler(struct k_work *work)
{
	int ret;

	ret = app_sensor_w1_therm_aggreg();
	if (ret) {
		LOG_ERR("Call `app_sensor_w1_therm_aggreg` failed: %d", ret);
	}
}

static K_WORK_DEFINE(m_w1_therm_aggreg_work, w1_therm_aggreg_work_handler);

static void w1_therm_aggreg_timer_handler(struct k_timer *timer)
{
	int ret;

	ret = k_work_submit_to_queue(&m_work_q, &m_w1_therm_aggreg_work);
	if (ret < 0) {
		LOG_ERR("Call `k_work_submit_to_queue` failed: %d", ret);
	}
}

static K_TIMER_DEFINE(m_w1_therm_aggreg_timer, w1_therm_aggreg_timer_handler, NULL);

#endif /* defined(CONFIG_SHIELD_CTR_DS18B20) */

#if defined(CONFIG_SHIELD_CTR_Z)

static void backup_work_handler(struct k_work *work)
{
	int ret;

	ret = app_backup_sample();
	if (ret < 0) {
		LOG_ERR("Call `app_backup_sample` failed: %d", ret);
	}
}

static K_WORK_DEFINE(m_backup_work, backup_work_handler);

void app_work_backup_update(void)
{
	int ret;

	ret = k_work_submit_to_queue(&m_work_q, &m_backup_work);
	if (ret < 0) {
		LOG_ERR("Call `k_work_submit_to_queue` failed: %d", ret);
	}
}

#endif /* defined(CONFIG_SHIELD_CTR_Z) */

int app_work_init(void)
{
	k_work_queue_start(&m_work_q, m_work_q_stack, K_THREAD_STACK_SIZEOF(m_work_q_stack),
			   WORK_Q_PRIORITY, NULL);

	k_thread_name_set(&m_work_q.thread, "app_work");

	/* Delay first report so ctr_z updates line_present */
	k_timer_start(&m_send_timer, K_SECONDS(2), K_FOREVER);
	k_timer_start(&m_sample_timer, K_NO_WAIT, K_SECONDS(60));
	k_timer_start(&m_power_timer, K_SECONDS(60), K_HOURS(12));

#if defined(CONFIG_SHIELD_CTR_X0_A)
	k_timer_start(&m_counter_aggreg_timer, K_SECONDS(g_app_config.counter_interval_aggreg),
		      K_SECONDS(g_app_config.counter_interval_aggreg));
	k_timer_start(&m_analog_sample_timer, K_SECONDS(g_app_config.analog_interval_sample),
		      K_SECONDS(g_app_config.analog_interval_sample));
	k_timer_start(&m_analog_aggreg_timer, K_SECONDS(g_app_config.analog_interval_aggreg),
		      K_SECONDS(g_app_config.analog_interval_aggreg));
#endif /* defined(CONFIG_SHIELD_CTR_X0_A) */

#if defined(CONFIG_SHIELD_CTR_S2)
	k_timer_start(&m_hygro_sample_timer, K_SECONDS(g_app_config.analog_interval_sample),
		      K_SECONDS(g_app_config.analog_interval_sample));
	k_timer_start(&m_hygro_aggreg_timer, K_SECONDS(g_app_config.analog_interval_aggreg),
		      K_SECONDS(g_app_config.analog_interval_aggreg));
#endif /* defined(CONFIG_SHIELD_CTR_S2) */

#if defined(CONFIG_SHIELD_CTR_DS18B20)
	k_timer_start(&m_w1_therm_sample_timer, K_SECONDS(g_app_config.w1_therm_interval_sample),
		      K_SECONDS(g_app_config.w1_therm_interval_sample));
	k_timer_start(&m_w1_therm_aggreg_timer, K_SECONDS(g_app_config.w1_therm_interval_aggreg),
		      K_SECONDS(g_app_config.w1_therm_interval_aggreg));
#endif /* defined(CONFIG_SHIELD_CTR_DS18B20) */

	return 0;
}

void app_work_aggreg(void)
{
#if defined(CONFIG_SHIELD_CTR_X0_A)
	k_timer_start(&m_analog_aggreg_timer, K_NO_WAIT,
		      K_SECONDS(g_app_config.analog_interval_aggreg));
#endif /* defined(CONFIG_SHIELD_CTR_X0_A) */

#if defined(CONFIG_SHIELD_CTR_S2)
	k_timer_start(&m_hygro_aggreg_timer, K_NO_WAIT,
		      K_SECONDS(g_app_config.analog_interval_aggreg));
#endif /* defined(CONFIG_SHIELD_CTR_S2) */

#if defined(CONFIG_SHIELD_CTR_DS18B20)
	k_timer_start(&m_w1_therm_aggreg_timer, K_NO_WAIT,
		      K_SECONDS(g_app_config.w1_therm_interval_aggreg));
#endif /* defined(CONFIG_SHIELD_CTR_DS18B20) */
}

void app_work_sample(void)
{
	k_timer_start(&m_sample_timer, K_NO_WAIT, K_SECONDS(60));

#if defined(CONFIG_SHIELD_CTR_X0_A)
	k_timer_start(&m_analog_sample_timer, K_NO_WAIT,
		      K_SECONDS(g_app_config.analog_interval_sample));
#endif /* defined(CONFIG_SHIELD_CTR_X0_A) */

#if defined(CONFIG_SHIELD_CTR_S2)
	k_timer_start(&m_hygro_sample_timer, K_NO_WAIT,
		      K_SECONDS(g_app_config.analog_interval_sample));
#endif /* defined(CONFIG_SHIELD_CTR_S2) */

#if defined(CONFIG_SHIELD_CTR_DS18B20)
	k_timer_start(&m_w1_therm_sample_timer, K_NO_WAIT,
		      K_SECONDS(g_app_config.w1_therm_interval_sample));
#endif /* defined(CONFIG_SHIELD_CTR_DS18B20) */
}

void app_work_send(void)
{
	k_timer_start(&m_send_timer, K_NO_WAIT, K_FOREVER);
}
```
